VERSION "1.0"

NS_ :

BS_:

BU_: Engine Gateway Dashboard

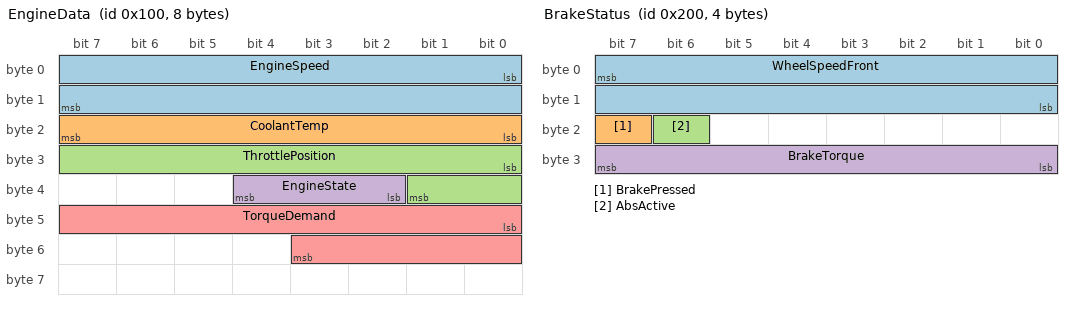
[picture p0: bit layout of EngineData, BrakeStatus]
BO_ 256 EngineData: 8 Engine
 SG_ EngineSpeed : 0|16@1+ (0.25,0) [0|16383.75] "rpm" Gateway,Dashboard
 SG_ CoolantTemp : 16|8@1+ (1,-40) [-40|215] "degC" Gateway,Dashboard
 SG_ ThrottlePosition : 24|10@1+ (0.1,0) [0|100] "%" Gateway
 SG_ EngineState : 34|3@1+ (1,0) [0|7] "" Gateway,Dashboard
 SG_ TorqueDemand : 40|12@1- (0.5,0) [-1024|1023.5] "Nm" Gateway

BO_ 512 BrakeStatus: 4 Gateway
 SG_ WheelSpeedFront : 7|16@0+ (0.01,0) [0|655.35] "km/h" Dashboard
 SG_ BrakePressed : 23|1@0+ (1,0) [0|1] "" Dashboard
 SG_ AbsActive : 22|1@0+ (1,0) [0|1] "" Dashboard
 SG_ BrakeTorque : 31|8@0- (1,0) [-128|127] "Nm" Dashboard

BO_ 2566844926 BatteryInfo: 8 Gateway
 SG_ PackVoltage : 0|32@1+ (1,0) [0|0] "V" Dashboard
 SG_ PackCurrent : 32|32@1- (0.001,0) [0|0] "A" Dashboard

BO_ 768 Odometer: 8 Dashboard
 SG_ Distance : 0|64@1+ (1,0) [0|0] "m" Gateway

CM_ BO_ 256 "Engine data broadcast by the engine control unit.";
CM_ SG_ 256 EngineSpeed "Crankshaft speed.";
CM_ SG_ 256 EngineState "State of the engine.";

BA_DEF_ BO_ "GenMsgCycleTime" INT 0 65535;
BA_DEF_DEF_ "GenMsgCycleTime" 0;
BA_ "GenMsgCycleTime" BO_ 256 10;
BA_ "GenMsgCycleTime" BO_ 512 20;

VAL_ 256 EngineState 0 "Off" 1 "Cranking" 2 "Running" 3 "Stalled" 4 "Fault";
VAL_ 512 BrakePressed 0 "Released" 1 "Pressed";
